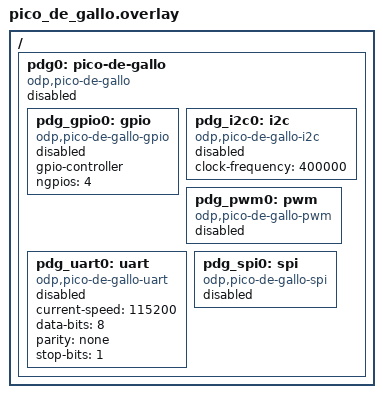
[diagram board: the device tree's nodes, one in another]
/*
 * Copyright (c) 2026 Open Device Partnership and Contributors
 *
 * SPDX-License-Identifier: MIT
 */

/ {
	pdg0: pico-de-gallo {
		compatible = "odp,pico-de-gallo";
		status = "disabled";

		pdg_gpio0: gpio {
			compatible = "odp,pico-de-gallo-gpio";
			gpio-controller;
			#gpio-cells = <2>;
			ngpios = <4>;
			status = "disabled";
		};

		pdg_i2c0: i2c {
			compatible = "odp,pico-de-gallo-i2c";
			clock-frequency = <400000>;
			#address-cells = <1>;
			#size-cells = <0>;
			status = "disabled";
		};

		pdg_pwm0: pwm {
			compatible = "odp,pico-de-gallo-pwm";
			#pwm-cells = <3>;
			status = "disabled";
		};

		pdg_uart0: uart {
			compatible = "odp,pico-de-gallo-uart";
			current-speed = <115200>;
			data-bits = <8>;
			parity = "none";
			stop-bits = "1";
			status = "disabled";
		};

		pdg_spi0: spi {
			compatible = "odp,pico-de-gallo-spi";
			#address-cells = <1>;
			#size-cells = <0>;
			status = "disabled";
		};
	};
};
